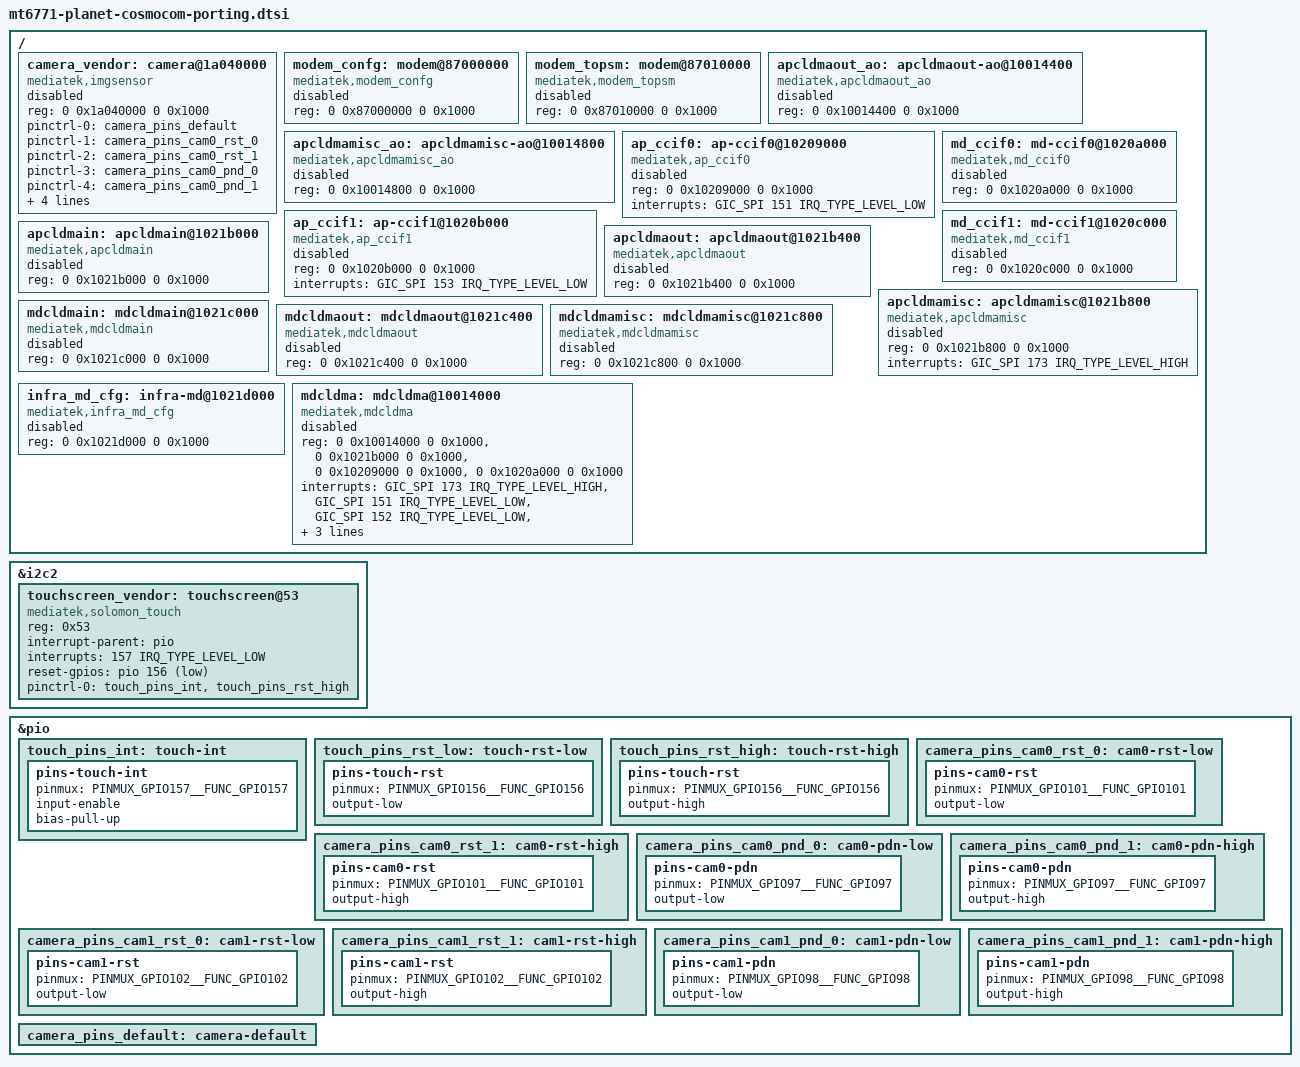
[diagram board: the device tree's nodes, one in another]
// SPDX-License-Identifier: GPL-2.0-only
/*
 * Phase 1 Cosmo bring-up scaffold.
 *
 * This file imports board wiring clues from the 4.4 vendor tree and keeps all
 * non-mainline blocks disabled by default. It provides anchor nodes for
 * incremental porting of touch, camera, and modem/cellular support.
 */

/ {
	/* 4.4 vendor camera framework placeholder (disabled in 6.4). */
	camera_vendor: camera@1a040000 {
		compatible = "mediatek,imgsensor";
		reg = <0 0x1a040000 0 0x1000>;
		status = "disabled";
		pinctrl-names = "default",
				"cam0-rst-low", "cam0-rst-high",
				"cam0-pdn-low", "cam0-pdn-high",
				"cam1-rst-low", "cam1-rst-high",
				"cam1-pdn-low", "cam1-pdn-high";
		pinctrl-0 = <&camera_pins_default>;
		pinctrl-1 = <&camera_pins_cam0_rst_0>;
		pinctrl-2 = <&camera_pins_cam0_rst_1>;
		pinctrl-3 = <&camera_pins_cam0_pnd_0>;
		pinctrl-4 = <&camera_pins_cam0_pnd_1>;
		pinctrl-5 = <&camera_pins_cam1_rst_0>;
		pinctrl-6 = <&camera_pins_cam1_rst_1>;
		pinctrl-7 = <&camera_pins_cam1_pnd_0>;
		pinctrl-8 = <&camera_pins_cam1_pnd_1>;
	};

	/* 4.4 modem register window placeholders (disabled in 6.4). */
	modem_confg: modem@87000000 {
		compatible = "mediatek,modem_confg";
		reg = <0 0x87000000 0 0x1000>;
		status = "disabled";
	};

	modem_topsm: modem@87010000 {
		compatible = "mediatek,modem_topsm";
		reg = <0 0x87010000 0 0x1000>;
		status = "disabled";
	};

	/* 4.4 modem control path building blocks (kept disabled for safe bring-up). */
	apcldmaout_ao: apcldmaout-ao@10014400 {
		compatible = "mediatek,apcldmaout_ao";
		reg = <0 0x10014400 0 0x1000>;
		status = "disabled";
	};

	apcldmamisc_ao: apcldmamisc-ao@10014800 {
		compatible = "mediatek,apcldmamisc_ao";
		reg = <0 0x10014800 0 0x1000>;
		status = "disabled";
	};

	ap_ccif0: ap-ccif0@10209000 {
		compatible = "mediatek,ap_ccif0";
		reg = <0 0x10209000 0 0x1000>;
		interrupts = <GIC_SPI 151 IRQ_TYPE_LEVEL_LOW>;
		status = "disabled";
	};

	md_ccif0: md-ccif0@1020a000 {
		compatible = "mediatek,md_ccif0";
		reg = <0 0x1020a000 0 0x1000>;
		status = "disabled";
	};

	ap_ccif1: ap-ccif1@1020b000 {
		compatible = "mediatek,ap_ccif1";
		reg = <0 0x1020b000 0 0x1000>;
		interrupts = <GIC_SPI 153 IRQ_TYPE_LEVEL_LOW>;
		status = "disabled";
	};

	md_ccif1: md-ccif1@1020c000 {
		compatible = "mediatek,md_ccif1";
		reg = <0 0x1020c000 0 0x1000>;
		status = "disabled";
	};

	apcldmain: apcldmain@1021b000 {
		compatible = "mediatek,apcldmain";
		reg = <0 0x1021b000 0 0x1000>;
		status = "disabled";
	};

	apcldmaout: apcldmaout@1021b400 {
		compatible = "mediatek,apcldmaout";
		reg = <0 0x1021b400 0 0x1000>;
		status = "disabled";
	};

	apcldmamisc: apcldmamisc@1021b800 {
		compatible = "mediatek,apcldmamisc";
		reg = <0 0x1021b800 0 0x1000>;
		interrupts = <GIC_SPI 173 IRQ_TYPE_LEVEL_HIGH>;
		status = "disabled";
	};

	mdcldmain: mdcldmain@1021c000 {
		compatible = "mediatek,mdcldmain";
		reg = <0 0x1021c000 0 0x1000>;
		status = "disabled";
	};

	mdcldmaout: mdcldmaout@1021c400 {
		compatible = "mediatek,mdcldmaout";
		reg = <0 0x1021c400 0 0x1000>;
		status = "disabled";
	};

	mdcldmamisc: mdcldmamisc@1021c800 {
		compatible = "mediatek,mdcldmamisc";
		reg = <0 0x1021c800 0 0x1000>;
		status = "disabled";
	};

	infra_md_cfg: infra-md@1021d000 {
		compatible = "mediatek,infra_md_cfg";
		reg = <0 0x1021d000 0 0x1000>;
		status = "disabled";
	};

	mdcldma: mdcldma@10014000 {
		compatible = "mediatek,mdcldma";
		reg = <0 0x10014000 0 0x1000>,
		      <0 0x1021b000 0 0x1000>,
		      <0 0x10209000 0 0x1000>,
		      <0 0x1020a000 0 0x1000>;
		interrupts = <GIC_SPI 173 IRQ_TYPE_LEVEL_HIGH>,
			     <GIC_SPI 151 IRQ_TYPE_LEVEL_LOW>,
			     <GIC_SPI 152 IRQ_TYPE_LEVEL_LOW>,
			     <GIC_SPI 283 IRQ_TYPE_EDGE_FALLING>;
		mediatek,md_id = <0>;
		mediatek,cldma_capability = <6>;
		status = "disabled";
	};
};

/* 4.4 used an SoC-local touch abstraction + vendor I2C driver. */
&i2c2 {
	touchscreen_vendor: touchscreen@53 {
		compatible = "mediatek,solomon_touch";
		reg = <0x53>;
		interrupt-parent = <&pio>;
		interrupts = <157 IRQ_TYPE_LEVEL_LOW>;
		reset-gpios = <&pio 156 GPIO_ACTIVE_LOW>;
		pinctrl-names = "default";
		pinctrl-0 = <&touch_pins_int &touch_pins_rst_high>;
		status = "okay";
	};
};

/* Camera and touch GPIO lines from the vendor board file. */
&pio {
	touch_pins_int: touch-int {
		pins-touch-int {
			pinmux = <PINMUX_GPIO157__FUNC_GPIO157>;
			input-enable;
			bias-pull-up;
		};
	};

	touch_pins_rst_low: touch-rst-low {
		pins-touch-rst {
			pinmux = <PINMUX_GPIO156__FUNC_GPIO156>;
			output-low;
		};
	};

	touch_pins_rst_high: touch-rst-high {
		pins-touch-rst {
			pinmux = <PINMUX_GPIO156__FUNC_GPIO156>;
			output-high;
		};
	};

	camera_pins_cam0_rst_0: cam0-rst-low {
		pins-cam0-rst {
			pinmux = <PINMUX_GPIO101__FUNC_GPIO101>;
			output-low;
		};
	};

	camera_pins_cam0_rst_1: cam0-rst-high {
		pins-cam0-rst {
			pinmux = <PINMUX_GPIO101__FUNC_GPIO101>;
			output-high;
		};
	};

	camera_pins_cam0_pnd_0: cam0-pdn-low {
		pins-cam0-pdn {
			pinmux = <PINMUX_GPIO97__FUNC_GPIO97>;
			output-low;
		};
	};

	camera_pins_cam0_pnd_1: cam0-pdn-high {
		pins-cam0-pdn {
			pinmux = <PINMUX_GPIO97__FUNC_GPIO97>;
			output-high;
		};
	};

	camera_pins_cam1_rst_0: cam1-rst-low {
		pins-cam1-rst {
			pinmux = <PINMUX_GPIO102__FUNC_GPIO102>;
			output-low;
		};
	};

	camera_pins_cam1_rst_1: cam1-rst-high {
		pins-cam1-rst {
			pinmux = <PINMUX_GPIO102__FUNC_GPIO102>;
			output-high;
		};
	};

	camera_pins_cam1_pnd_0: cam1-pdn-low {
		pins-cam1-pdn {
			pinmux = <PINMUX_GPIO98__FUNC_GPIO98>;
			output-low;
		};
	};

	camera_pins_cam1_pnd_1: cam1-pdn-high {
		pins-cam1-pdn {
			pinmux = <PINMUX_GPIO98__FUNC_GPIO98>;
			output-high;
		};
	};

	camera_pins_default: camera-default {
	};
};
